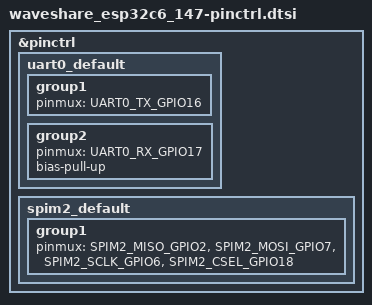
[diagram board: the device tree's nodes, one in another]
/*
 * Waveshare ESP32-C6 pinctrl
 */

#include <zephyr/dt-bindings/pinctrl/esp32c6-pinctrl.h>
#include <dt-bindings/pinctrl/esp32-pinctrl-common.h>

&pinctrl {
	uart0_default: uart0_default {
		group1 {
			pinmux = <UART0_TX_GPIO16>;
		};
		group2 {
			pinmux = <UART0_RX_GPIO17>;
			bias-pull-up;
		};
	};

	spim2_default: spim2_default {
		group1 {
			pinmux = <SPIM2_MISO_GPIO2>,
				 <SPIM2_MOSI_GPIO7>,
				 <SPIM2_SCLK_GPIO6>,
				 <SPIM2_CSEL_GPIO18>;
		};
	};
};
